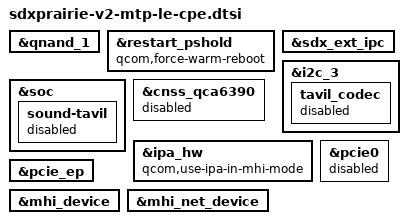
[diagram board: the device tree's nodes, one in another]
/* Copyright (c) 2019-2020, The Linux Foundation. All rights reserved.
 *
 * This program is free software; you can redistribute it and/or modify
 * it under the terms of the GNU General Public License version 2 and
 * only version 2 as published by the Free Software Foundation.
 *
 * This program is distributed in the hope that it will be useful,
 * but WITHOUT ANY WARRANTY; without even the implied warranty of
 * MERCHANTABILITY or FITNESS FOR A PARTICULAR PURPOSE.  See the
 * GNU General Public License for more details.
 */

#include "sdxprairie-v2.dtsi"
#include "sdxprairie-cpe-memory-map.dtsi"
#include "sdxprairie-mtp.dtsi"

&qnand_1 {
	status = "ok";
};

&restart_pshold {
	qcom,force-warm-reboot;
};

&sdx_ext_ipc {
	status = "ok";
};

&i2c_3 {
	tavil_codec {
		status = "disabled";
	};
};

&soc {
	sound-tavil {
		status = "disabled";
	};
};

&cnss_qca6390 {
	status = "disabled";
};

&ipa_hw {
	qcom,use-ipa-in-mhi-mode;
};

&pcie0 {
	status = "disabled";
};

&pcie_ep {
	status = "ok";
};

&mhi_device {
	status = "ok";
};

&mhi_net_device {
	status = "ok";
};
